# STM32H563 register map
File version: 1.8
CPU: CM33 r0p0, little endian, MPU, FPU, 4 interrupt priority bits
Registers are 32-bit, read-write, reset 0x0 unless marked. A register's access mark holds for its fields unless they carry their own. Offsets are from the block's base; [hi:lo] are bit positions; {n}, {i} and the like mark numbered series.

## ICACHE — Instruction cache
Base 0x40030400
Same registers: SEC_ICACHE 0x50030400
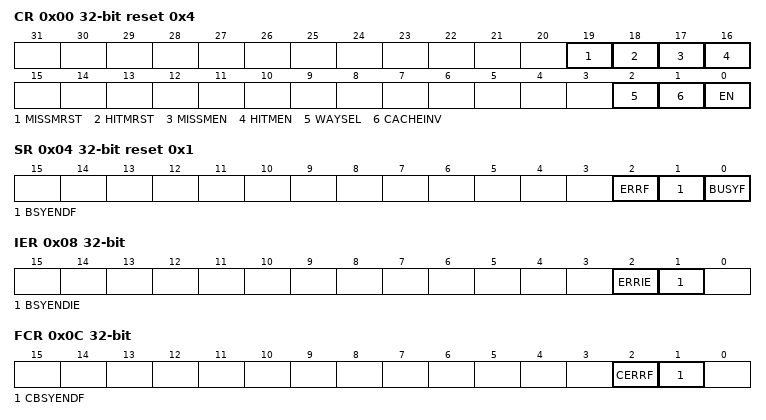
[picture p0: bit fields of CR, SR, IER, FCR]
0x00 CR access per field reset 0x4 — ICACHE control register
  [19] MISSMRST rw — miss monitor reset
  [18] HITMRST rw — hit monitor reset
  [17] MISSMEN rw — miss monitor enable
  [16] HITMEN rw — hit monitor enable
  [2] WAYSEL rw — cache associativity mode selection This bit allows user to choose ICACHE set-associativity. It can be written by software only when cache is disabled (EN = 0).
  [1] CACHEINV wo — cache invalidation Set by software and cleared by hardware when the BUSYF flag is set (during cache maintenance operation). Writing 0 has no effect.
  [0] EN rw — enable
0x04 SR ro reset 0x1 — ICACHE status register
  [2] ERRF — cache error flag
  [1] BSYENDF — busy end flag
  [0] BUSYF — busy flag
0x08 IER — ICACHE interrupt enable register
  [2] ERRIE — interrupt enable on cache error Set by software to enable an interrupt generation in case of cache functional error (cacheable write access)
  [1] BSYENDIE — interrupt enable on busy end Set by software to enable an interrupt generation at the end of a cache invalidate operation.
0x0C FCR wo — ICACHE flag clear register
  [2] CERRF — clear cache error flag Set by software.
  [1] CBSYENDF — clear busy end flag Set by software.
0x10 HMONR ro — ICACHE hit monitor register
  [31:0] HITMON — cache hit monitor counter
0x14 MMONR ro — ICACHE miss monitor register
  [15:0] MISSMON — cache miss monitor counter
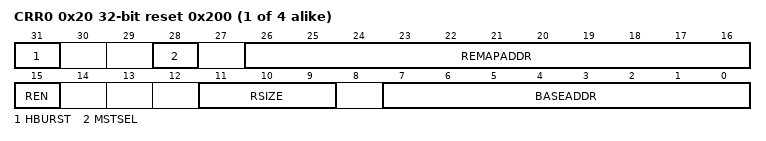
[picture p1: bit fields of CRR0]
{0x20+4i} CRR{i} reset 0x200 (i=0..3) — ICACHE region {i} configuration register
  [31] HBURST — output burst type for region x
  [28] MSTSEL — AHB cache master selection for region x
  [26:16] REMAPADDR — remapped address for region x This field replaces the alias address defined by BASEADDR field. The only useful bits are [31:RI], where 21 less than or equal RI less than or equal 27 is the number of bits of RSIZE (see ). If the programmed value has more LSBs, the useless bits are ignored.
  [15] REN — enable for region x
  [11:9] RSIZE — size for region x
  [7:0] BASEADDR — base address for region x This alias address is replaced by REMAPADDR field. The only useful bits are [28:RI], where 21 less than or equal RI less than or equal 27 is the number of bits of RSIZE (see ). If the programmed value has more LSBs, the useless bits are ignored.

## VREFBUF — Voltage reference buffer
Base 0x44007400
Same registers: SEC_VREFBUF 0x54007400
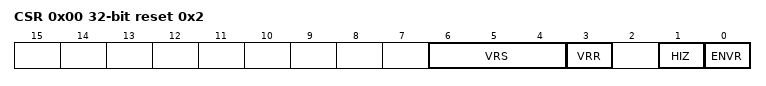
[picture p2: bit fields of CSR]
0x00 CSR access per field reset 0x2 — VREFBUF control and status register
  [6:4] VRS rw — Voltage reference scale These bits select the value generated by the voltage reference buffer. VRS = 000: VREFBUF0 voltage selected. VRS = 001: VREFBUF1 voltage selected. VRS = 010: VREFBUF2 voltage selected. VRS = 011: VREFBUF3 voltage selected. Others: Reserved Note: Refer to the product datasheet for each VREFBUFx voltage setting value. The software can program this bitfield only when the VREFBUF is disabled (ENVR=0).
  [3] VRR ro — Voltage reference buffer ready
  [1] HIZ rw — High impedance mode This bit controls the analog switch to connect or not the VREF+ pin. Refer to for the mode descriptions depending on ENVR bit configuration.
  [0] ENVR rw — Voltage reference buffer mode enable This bit is used to enable the voltage reference buffer mode.
0x04 CCR (reset mask 0xFFFFFF00) — VREFBUF calibration control register
  [5:0] TRIM — Trimming code The TRIM code is a 6-bit unsigned data (minimum 000000, maximum 111111) that is set and updated according the mechanism described below. Reset: TRIM[5:0] is automatically initialized with the VRS = 0 trimming value stored in the Flash memory during the production test. VRS change: TRIM[5:0] is automatically initialized with the trimming value (corresponding to VRS setting) stored in the Flash memory during the production test. Write in TRIM[5:0]: User can modify the TRIM[5:0] with an arbitrary value. This is permanently disabling the control of the trimming value with VRS (until the device is reset). Note: If the user application performs the trimming, the trimming code must start from 000000 to 111111 in ascending order.

## WWDG — System window watchdog
Base 0x40002C00
Same registers: SEC_WWDG 0x50002C00
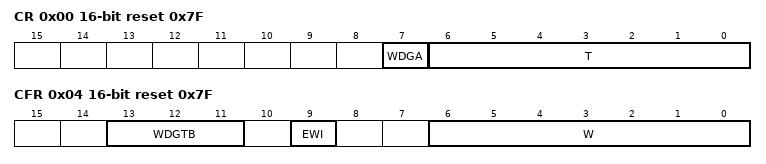
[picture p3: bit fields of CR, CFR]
0x00 CR 16-bit reset 0x7F — WWDG control register
  [7] WDGA — Activation bit This bit is set by software and only cleared by hardware after a reset. When WDGA = 1, the watchdog can generate a reset.
    0=Disabled (Watchdog disabled); 1=Enabled (Watchdog enabled)
  [6:0] T — 7-bit counter (MSB to LSB) These bits contain the value of the watchdog counter, decremented every (4096 x 2WDGTB[2:0]) PCLK cycles. A reset is produced when it is decremented from 0x40 to 0x3F (T6 becomes cleared).
0x04 CFR 16-bit access not given reset 0x7F — WWDG configuration register
  [13:11] WDGTB — Timer base The timebase of the prescaler can be modified as follows:
    0=Div1 (Counter clock (PCLK1 div 4096) div 1); 1=Div2 (Counter clock (PCLK1 div 4096) div 2); 2=Div4 (Counter clock (PCLK1 div 4096) div 4); 3=Div8 (Counter clock (PCLK1 div 4096) div 8); 4=Div16 (Counter clock (PCLK1 div 4096) div 16); 5=Div32 (Counter clock (PCLK1 div 4096) div 32); 6=Div64 (Counter clock (PCLK1 div 4096) div 64); 7=Div128 (Counter clock (PCLK1 div 4096) div 128)
  [9] EWI rw — Early wakeup interrupt When set, an interrupt occurs whenever the counter reaches the value 0x40. This interrupt is only cleared by hardware after a reset.
    on write: 1=Enable (interrupt occurs whenever the counter reaches the value 0x40)
  [6:0] W rw — 7-bit window value These bits contain the window value to be compared with the down-counter.
0x08 SR 16-bit — WWDG status register
  [0] EWIF write-0-clears — Early wakeup interrupt flag This bit is set by hardware when the counter has reached the value 0x40. It must be cleared by software by writing '0'. Writing '1' has no effect. This bit is also set if the interrupt is not enabled.
    on read: 0=Finished (The EWI Interrupt Service Routine has been serviced); 1=Pending (The EWI Interrupt Service Routine has been triggered) | on write: 0=Finished (The EWI Interrupt Service Routine has been serviced)
